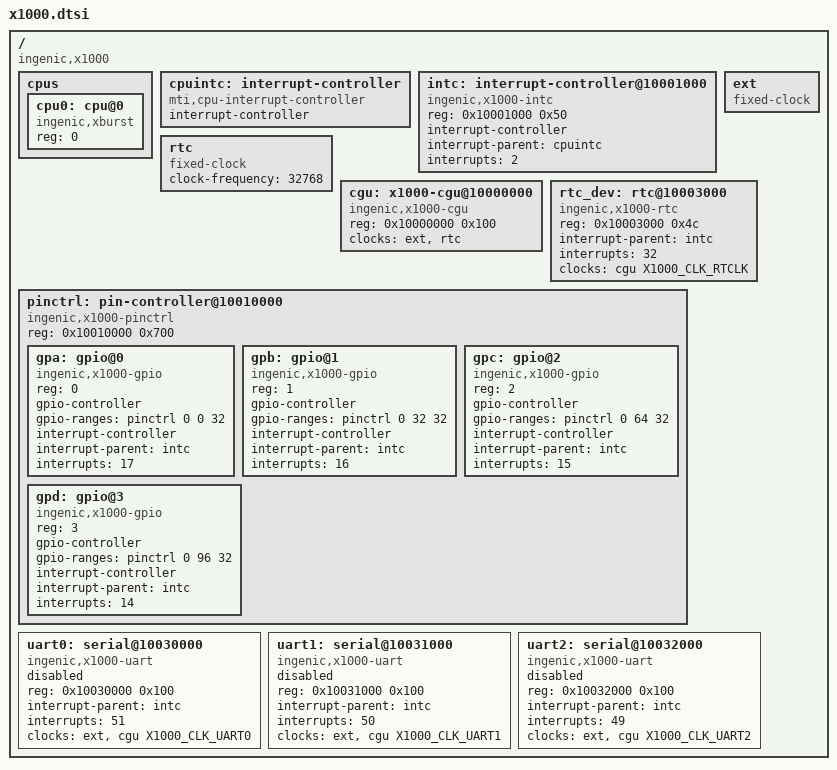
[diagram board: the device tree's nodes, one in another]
// SPDX-License-Identifier: GPL-2.0
#include <dt-bindings/clock/x1000-cgu.h>

/ {
	#address-cells = <1>;
	#size-cells = <1>;
	compatible = "ingenic,x1000", "ingenic,x1000e";

	cpus {
		#address-cells = <1>;
		#size-cells = <0>;

		cpu0: cpu@0 {
			compatible = "ingenic,xburst";
			device_type = "cpu";
			reg = <0>;
		};
	};

	cpuintc: interrupt-controller {
		#address-cells = <0>;
		#interrupt-cells = <1>;
		interrupt-controller;
		compatible = "mti,cpu-interrupt-controller";
	};

	intc: interrupt-controller@10001000 {
		compatible = "ingenic,x1000-intc";
		reg = <0x10001000 0x50>;

		interrupt-controller;
		#interrupt-cells = <1>;

		interrupt-parent = <&cpuintc>;
		interrupts = <2>;
	};

	ext: ext {
		compatible = "fixed-clock";
		#clock-cells = <0>;
	};

	rtc: rtc {
		compatible = "fixed-clock";
		#clock-cells = <0>;
		clock-frequency = <32768>;
	};

	cgu: x1000-cgu@10000000 {
		compatible = "ingenic,x1000-cgu";
		reg = <0x10000000 0x100>;

		clocks = <&ext>, <&rtc>;
		clock-names = "ext", "rtc";

		#clock-cells = <1>;
		//little-endian; ?????
	};

	rtc_dev: rtc@10003000 {
		compatible = "ingenic,x1000-rtc";
		reg = <0x10003000 0x4c>;

		interrupt-parent = <&intc>;
		interrupts = <32>;

		clocks = <&cgu X1000_CLK_RTCLK>;
		clock-names = "rtc";
	};

	pinctrl: pin-controller@10010000 {
		compatible = "ingenic,x1000-pinctrl";
		reg = <0x10010000 0x700>;//??

		#address-cells = <1>;
		#size-cells = <0>;

		gpa: gpio@0 {
			compatible = "ingenic,x1000-gpio";
			reg = <0>;

			gpio-controller;
			gpio-ranges = <&pinctrl 0 0 32>;
			#gpio-cells = <2>;

			interrupt-controller;
			#interrupt-cells = <2>;

			interrupt-parent = <&intc>;
			interrupts = <17>;
		};

		gpb: gpio@1 {
			compatible = "ingenic,x1000-gpio";
			reg = <1>;

			gpio-controller;
			gpio-ranges = <&pinctrl 0 32 32>;
			#gpio-cells = <2>;

			interrupt-controller;
			#interrupt-cells = <2>;

			interrupt-parent = <&intc>;
			interrupts = <16>;
		};

		gpc: gpio@2 {
			compatible = "ingenic,x1000-gpio";
			reg = <2>;

			gpio-controller;
			gpio-ranges = <&pinctrl 0 64 32>;
			#gpio-cells = <2>;

			interrupt-controller;
			#interrupt-cells = <2>;

			interrupt-parent = <&intc>;
			interrupts = <15>;
		};

		gpd: gpio@3 {
			compatible = "ingenic,x1000-gpio";
			reg = <3>;

			gpio-controller;
			gpio-ranges = <&pinctrl 0 96 32>;
			#gpio-cells = <2>;

			interrupt-controller;
			#interrupt-cells = <2>;

			interrupt-parent = <&intc>;
			interrupts = <14>;
		};
	};

	uart0: serial@10030000 {
		compatible = "ingenic,x1000-uart";
		reg = <0x10030000 0x100>;

		interrupt-parent = <&intc>;
		interrupts = <51>;

		clocks = <&ext>, <&cgu X1000_CLK_UART0>;
		clock-names = "baud", "module";

		status = "disabled";
	};

	uart1: serial@10031000 {
		compatible = "ingenic,x1000-uart";
		reg = <0x10031000 0x100>;

		interrupt-parent = <&intc>;
		interrupts = <50>;

		clocks = <&ext>, <&cgu X1000_CLK_UART1>;
		clock-names = "baud", "module";

		status = "disabled";
	};

	uart2: serial@10032000 {
		compatible = "ingenic,x1000-uart";
		reg = <0x10032000 0x100>;

		interrupt-parent = <&intc>;
		interrupts = <49>;

		clocks = <&ext>, <&cgu X1000_CLK_UART2>;
		clock-names = "baud", "module";

		status = "disabled";
	};
};
